# PY32F040Exx register map
Vendor: Puya; Series: PY32F0; File version: 1.0.0
CPU: CM0+ r0p1, little endian, no MPU, no FPU, 4 interrupt priority bits
Registers are 32-bit, read-write, reset 0x0 unless marked. A register's access mark holds for its fields unless they carry their own. Offsets are from the block's base; [hi:lo] are bit positions; {n}, {i} and the like mark numbered series.

## I2C1 — Inter integrated circuit
Base 0x40005400
Same registers: I2C2 0x40005800
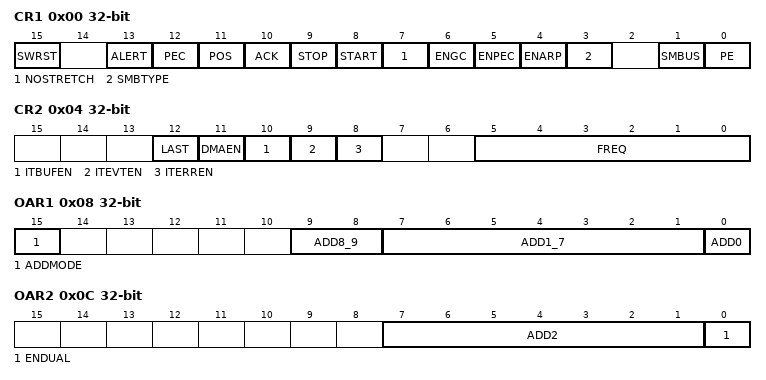
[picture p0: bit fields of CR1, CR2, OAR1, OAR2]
0x00 CR1
  [15] SWRST, [13] ALERT, [12] PEC, [11] POS, [10] ACK, [9] STOP, [8] START, [7] NOSTRETCH, [6] ENGC, [5] ENPEC, [4] ENARP, [3] SMBTYPE, [1] SMBUS, [0] PE
0x04 CR2
  [12] LAST, [11] DMAEN, [10] ITBUFEN, [9] ITEVTEN, [8] ITERREN, [5:0] FREQ
0x08 OAR1
  [15] ADDMODE, [9:8] ADD8_9, [7:1] ADD1_7, [0] ADD0
0x0C OAR2
  [7:1] ADD2, [0] ENDUAL
0x10 DR
  [7:0] DR
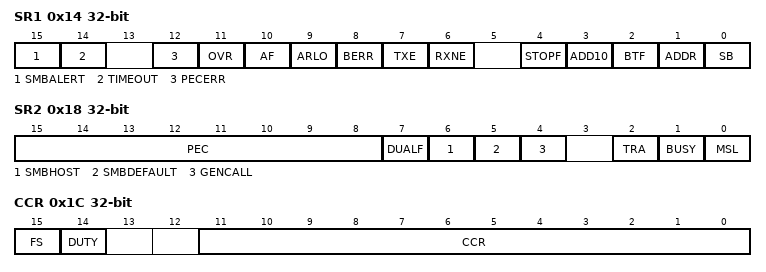
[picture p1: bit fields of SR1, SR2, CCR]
0x14 SR1
  [15] SMBALERT, [14] TIMEOUT, [12] PECERR, [11] OVR, [10] AF, [9] ARLO, [8] BERR, [7] TXE ro, [6] RXNE ro, [4] STOPF ro, [3] ADD10 ro, [2] BTF ro, [1] ADDR ro, [0] SB ro
0x18 SR2 ro
  [15:8] PEC, [7] DUALF, [6] SMBHOST, [5] SMBDEFAULT, [4] GENCALL, [2] TRA, [1] BUSY, [0] MSL
0x1C CCR
  [15] FS, [14] DUTY, [11:0] CCR
0x20 TRISE reset 0x2
  [5:0] TRISE

## IWDG — Independent watchdog
Base 0x40003000
0x00 KR wo — Key register (IWDG_KR)
  [15:0] KEY — Key value
0x04 PR — Prescaler register (IWDG_PR)
  [2:0] PR — Prescaler divider
0x08 RLR reset 0xFFF — Reload register (IWDG_RLR)
  [11:0] RL — Watchdog counter reload value
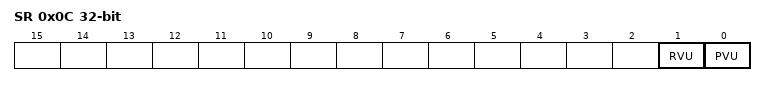
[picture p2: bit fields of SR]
0x0C SR ro — Status register (IWDG_SR)
  [1] RVU — Watchdog counter reload value update
  [0] PVU — Watchdog prescaler value update

## LCD — LCD CONTROLLER
Base 0x40002400
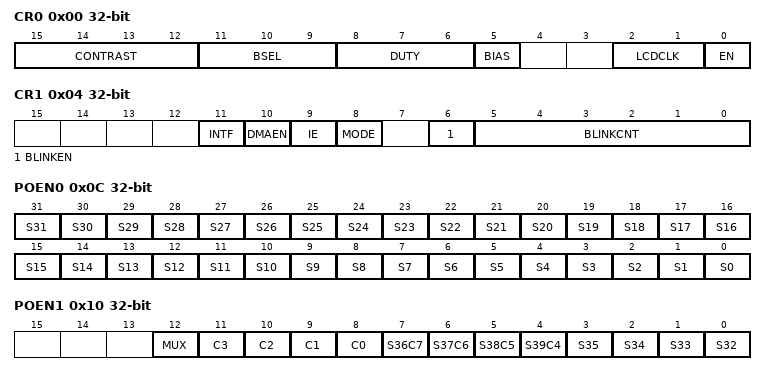
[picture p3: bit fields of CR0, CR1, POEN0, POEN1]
0x00 CR0 — Control register
  [15:12] CONTRAST, [11:9] BSEL, [8:6] DUTY, [5] BIAS, [2:1] LCDCLK, [0] EN
0x04 CR1
  [11] INTF, [10] DMAEN, [9] IE, [8] MODE, [6] BLINKEN, [5:0] BLINKCNT
0x08 INTCLR
  [10] INTF_CLR
0x0C POEN0
  [n] S{n} (n=0..31)
0x10 POEN1
  [12] MUX
  [n+8] C{n} (n=0..3)
  [7] S36C7 — S36
  [6] S37C6 — S37
  [5] S38C5 — S38
  [4] S39C4 — S39
  [n-32] S{n} (n=32..35)
{0x14+4i} RAM{i} (i=0..7) — des RAM{i}
  [31:0] D — des D
{0x14+4i} RAM{i} (i=8..15) — des RAM{i}
  [7:0] D — des D

## LPTIM1 — Low power timer
Base 0x40007C00
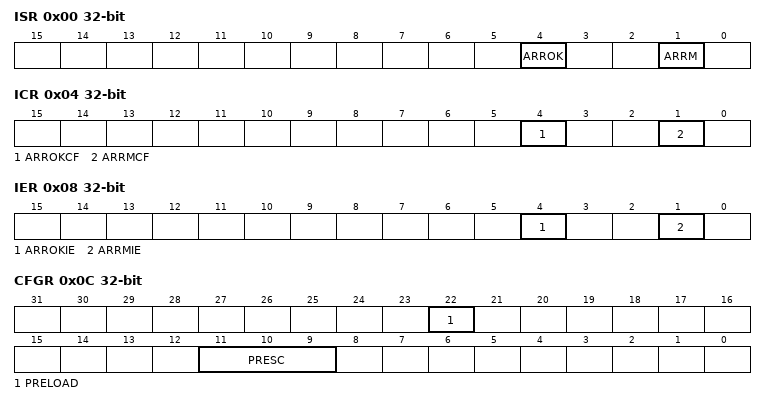
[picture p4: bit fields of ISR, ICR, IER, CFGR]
0x00 ISR ro — Interrupt and Status Register
  [4] ARROK — Autoreload match update OK
  [1] ARRM — Autoreload match
0x04 ICR wo — Interrupt Clear Register
  [4] ARROKCF — Autoreload match update OK Clear Flag
  [1] ARRMCF — Autoreload match Clear Flag
0x08 IER — Interrupt Enable Register
  [4] ARROKIE — Autoreload match update OK Interrupt Enable
  [1] ARRMIE — Autoreload matchInterrupt Enable
0x0C CFGR — Configuration Register
  [22] PRELOAD — Registers update mode
  [11:9] PRESC — Clock prescaler
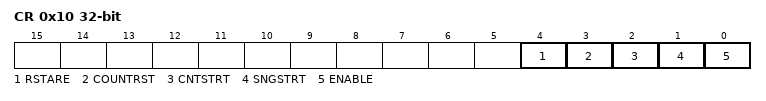
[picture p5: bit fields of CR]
0x10 CR — Control Register
  [4] RSTARE — Reset after read enable
  [3] COUNTRST — LPTIM counter reset
  [2] CNTSTRT
  [1] SNGSTRT — LPTIM start in single mode
  [0] ENABLE — LPTIM Enable
0x18 ARR reset 0x1 — Autoreload Register
  [15:0] ARR — Auto reload value
0x1C CNT ro — Counter Register
  [15:0] CNT — Counter value

## OPA — des OPA
Base 0x40010300
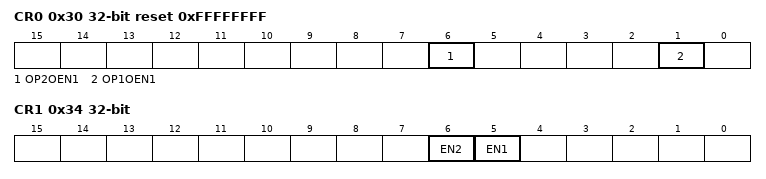
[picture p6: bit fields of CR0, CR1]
0x30 CR0 reset 0xFFFFFFFF
  [6] OP2OEN1, [1] OP1OEN1
0x34 CR1
  [6] EN2, [5] EN1

## PWR — Power control
Base 0x40007000
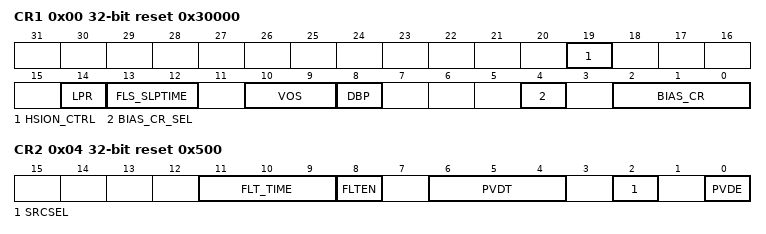
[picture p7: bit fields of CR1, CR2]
0x00 CR1 reset 0x30000 — Power control register 1
  [19] HSION_CTRL — HSI open time control
  [14] LPR — Low-power run
  [13:12] FLS_SLPTIME — Flash wait time after wakeup from the stop mode
  [10:9] VOS — Voltage scaling range selection
  [8] DBP — Disable backup domain write protection
  [4] BIAS_CR_SEL — MR Bias current selection
  [2:0] BIAS_CR — MR Bias current
0x04 CR2 reset 0x500 — Power control register 2
  [11:9] FLT_TIME — Digital filter time configuration
  [8] FLTEN — Digital filter enable
  [6:4] PVDT — Power voltage detector threshold selection
  [2] SRCSEL — Power voltage detector volatage selection
  [0] PVDE — Power voltage detector enable
0x14 SR ro — Power status register
  [11] PVDO — PVD output

## RTC
Base 0x40002800
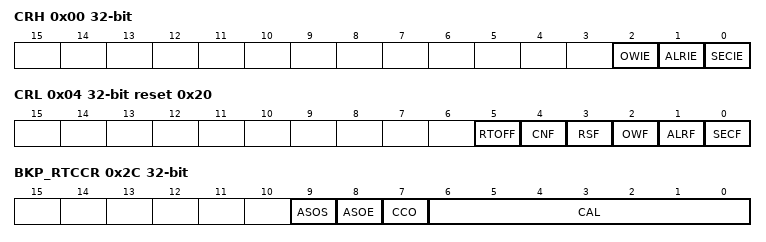
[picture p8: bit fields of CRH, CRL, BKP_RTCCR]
0x00 CRH
  [2] OWIE, [1] ALRIE, [0] SECIE
0x04 CRL reset 0x20
  [5] RTOFF ro, [4] CNF, [3] RSF, [2] OWF, [1] ALRF, [0] SECF
0x08 PRLH wo
  [3:0] PRL
0x0C PRLL wo reset 0x8000
  [15:0] PRL
0x10 DIVH ro
  [3:0] DIV
0x14 DIVL ro reset 0x8000
  [15:0] DIV
0x18 CNTH
  [15:0] RTC_CNT
0x1C CNTL
  [15:0] RTC_CNT
0x20 ALRH reset 0xFFFF
  [15:0] RTC_ALR
0x24 ALRL reset 0xFFFF
  [15:0] RTC_ALR
0x2C BKP_RTCCR
  [9] ASOS, [8] ASOE, [7] CCO, [6:0] CAL

## SPI1 — Serial peripheral interface
Base 0x40013000
Same registers: SPI2 0x40003800
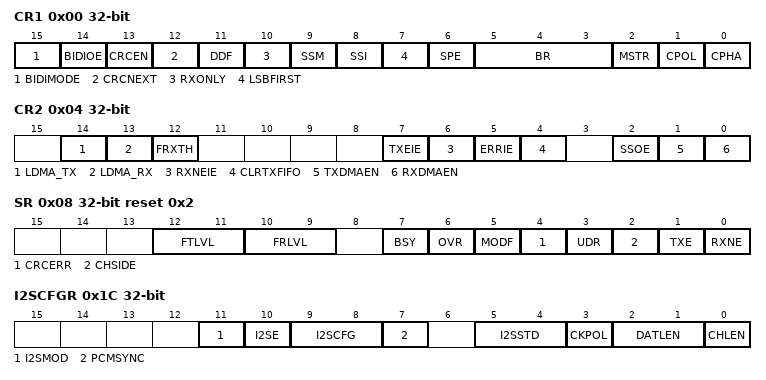
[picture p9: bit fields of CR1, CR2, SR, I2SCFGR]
0x00 CR1
  [15] BIDIMODE, [14] BIDIOE, [13] CRCEN, [12] CRCNEXT, [11] DDF, [10] RXONLY, [9] SSM, [8] SSI, [7] LSBFIRST, [6] SPE, [5:3] BR, [2] MSTR, [1] CPOL, [0] CPHA
0x04 CR2
  [14] LDMA_TX, [13] LDMA_RX, [12] FRXTH, [7] TXEIE, [6] RXNEIE, [5] ERRIE, [4] CLRTXFIFO, [2] SSOE, [1] TXDMAEN, [0] RXDMAEN
0x08 SR reset 0x2
  [12:11] FTLVL ro, [10:9] FRLVL ro, [7] BSY ro, [6] OVR ro, [5] MODF ro, [4] CRCERR, [3] UDR ro, [2] CHSIDE ro, [1] TXE ro, [0] RXNE ro
0x0C DR
  [15:0] DR
0x10 CRCPR reset 0x7
  [15:0] CRCPOLY
0x14 RXCRCR ro
  [15:0] RXCRC
0x18 TXCRCR ro
  [15:0] TXCRC
0x1C I2SCFGR
  [11] I2SMOD, [10] I2SE, [9:8] I2SCFG, [7] PCMSYNC, [5:4] I2SSTD, [3] CKPOL, [2:1] DATLEN, [0] CHLEN
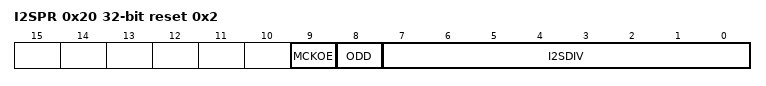
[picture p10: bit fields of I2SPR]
0x20 I2SPR reset 0x2
  [9] MCKOE, [8] ODD, [7:0] I2SDIV

## SYSCFG
Base 0x40010000
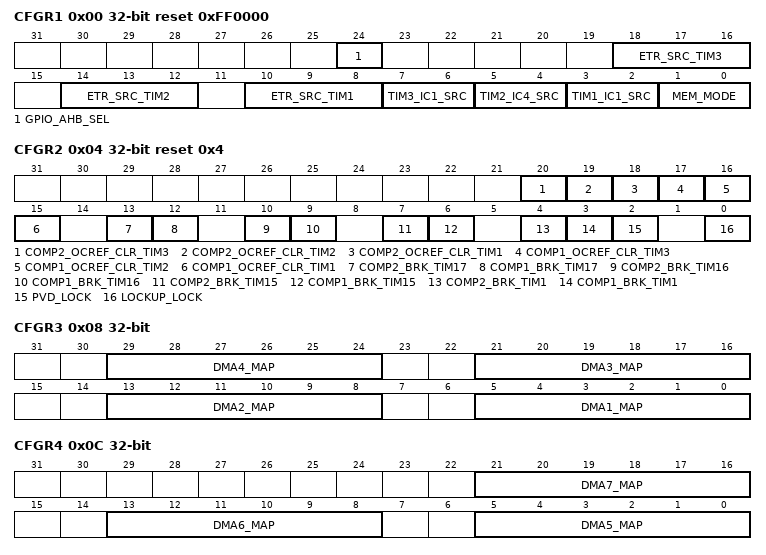
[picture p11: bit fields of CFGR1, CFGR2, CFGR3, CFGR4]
0x00 CFGR1 reset 0xFF0000
  [24] GPIO_AHB_SEL, [18:16] ETR_SRC_TIM3, [14:12] ETR_SRC_TIM2, [10:8] ETR_SRC_TIM1, [7:6] TIM3_IC1_SRC, [5:4] TIM2_IC4_SRC, [3:2] TIM1_IC1_SRC, [1:0] MEM_MODE
0x04 CFGR2 reset 0x4
  [20] COMP2_OCREF_CLR_TIM3, [19] COMP2_OCREF_CLR_TIM2, [18] COMP2_OCREF_CLR_TIM1, [17] COMP1_OCREF_CLR_TIM3, [16] COMP1_OCREF_CLR_TIM2, [15] COMP1_OCREF_CLR_TIM1, [13] COMP2_BRK_TIM17, [12] COMP1_BRK_TIM17, [10] COMP2_BRK_TIM16, [9] COMP1_BRK_TIM16, [7] COMP2_BRK_TIM15, [6] COMP1_BRK_TIM15, [4] COMP2_BRK_TIM1, [3] COMP1_BRK_TIM1, [2] PVD_LOCK, [0] LOCKUP_LOCK
0x08 CFGR3
  [8n-3:8n-8] DMA{n}_MAP (n=1..4)
0x0C CFGR4
  [21:16] DMA7_MAP, [13:8] DMA6_MAP, [5:0] DMA5_MAP
0x10 PAENS
  [15:0] PA_ENS
0x14 PBENS
  [15:0] PB_ENS
0x18 PCENS
  [15:0] PC_ENS
0x1C PFENS
  [15:0] PF_ENS
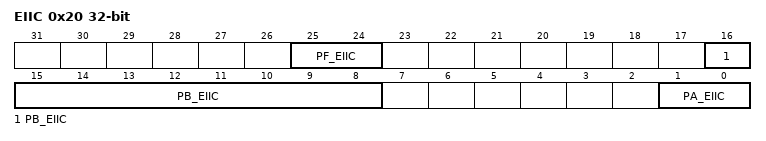
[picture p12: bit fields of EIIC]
0x20 EIIC
  [25:24] PF_EIIC, [16:8] PB_EIIC, [1:0] PA_EIIC

## USART1 — Universal synchronous asynchronous receiver transmitter
Base 0x40013800
Same registers: USART2 0x40004400, USART3 0x40004800, USART4 0x40004C00
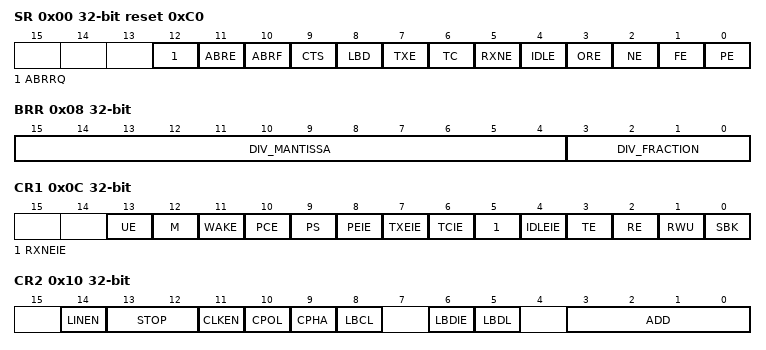
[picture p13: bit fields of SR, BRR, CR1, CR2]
0x00 SR reset 0xC0
  [12] ABRRQ wo, [11] ABRE ro, [10] ABRF ro, [9] CTS, [8] LBD, [7] TXE ro, [6] TC, [5] RXNE, [4] IDLE ro, [3] ORE ro, [2] NE ro, [1] FE ro, [0] PE ro
0x04 DR
  [8:0] DR
0x08 BRR
  [15:4] DIV_MANTISSA, [3:0] DIV_FRACTION
0x0C CR1
  [13] UE, [12] M, [11] WAKE, [10] PCE, [9] PS, [8] PEIE, [7] TXEIE, [6] TCIE, [5] RXNEIE, [4] IDLEIE, [3] TE, [2] RE, [1] RWU, [0] SBK
0x10 CR2
  [14] LINEN, [13:12] STOP, [11] CLKEN, [10] CPOL, [9] CPHA, [8] LBCL, [6] LBDIE, [5] LBDL, [3:0] ADD
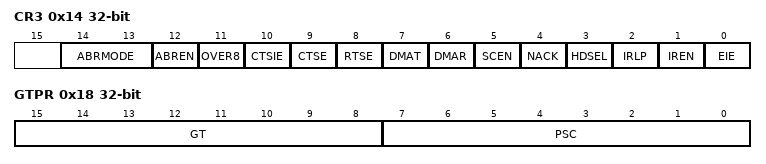
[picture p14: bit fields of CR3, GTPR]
0x14 CR3
  [14:13] ABRMODE, [12] ABREN, [11] OVER8, [10] CTSIE, [9] CTSE, [8] RTSE, [7] DMAT, [6] DMAR, [5] SCEN, [4] NACK, [3] HDSEL, [2] IRLP, [1] IREN, [0] EIE
0x18 GTPR
  [15:8] GT, [7:0] PSC

## WWDG — Window watchdog
Base 0x40002C00
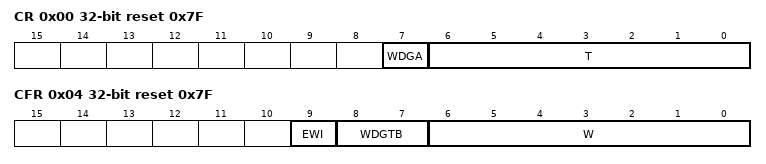
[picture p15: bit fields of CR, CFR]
0x00 CR reset 0x7F — Control register (WWDG_CR)
  [7] WDGA — Activation bit
  [6:0] T — 7-bit counter (MSB to LSB)
0x04 CFR reset 0x7F — Configuration register (WWDG_CFR)
  [9] EWI — Early Wakeup Interrupt
  [8:7] WDGTB — Timer Base
  [6:0] W — 7-bit window value
0x08 SR — Status register (WWDG_SR)
  [0] EWIF — Early Wakeup Interrupt flag
